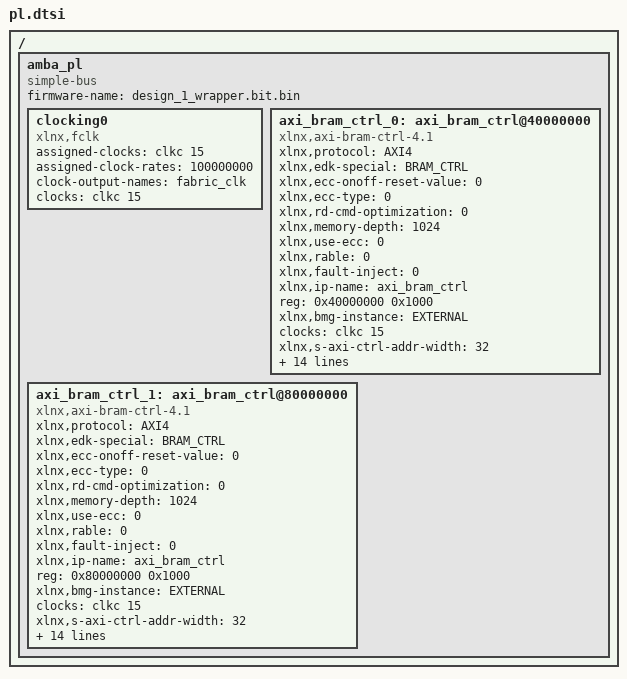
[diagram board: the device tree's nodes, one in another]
/ {
	amba_pl: amba_pl {
		ranges;
		compatible = "simple-bus";
		#address-cells = <1>;
		#size-cells = <1>;
		firmware-name = "design_1_wrapper.bit.bin";
		clocking0: clocking0 {
			compatible = "xlnx,fclk";
			assigned-clocks = <&clkc 15>;
			assigned-clock-rates = <100000000>;
			#clock-cells = <0>;
			clock-output-names = "fabric_clk";
			clocks = <&clkc 15>;
		};
		axi_bram_ctrl_0: axi_bram_ctrl@40000000 {
			xlnx,protocol = "AXI4";
			xlnx,edk-special = "BRAM_CTRL";
			compatible = "xlnx,axi-bram-ctrl-4.1";
			xlnx,ecc-onoff-reset-value = <0>;
			xlnx,ecc-type = <0>;
			xlnx,rd-cmd-optimization = <0>;
			xlnx,memory-depth = <1024>;
			xlnx,use-ecc = <0>;
			xlnx,rable = <0>;
			xlnx,fault-inject = <0>;
			xlnx,ip-name = "axi_bram_ctrl";
			reg = <0x40000000 0x1000>;
			xlnx,bmg-instance = "EXTERNAL";
			clocks = <&clkc 15>;
			xlnx,s-axi-ctrl-addr-width = <32>;
			xlnx,read-latency = <1>;
			xlnx,id-width = <0>;
			xlnx,s-axi-supports-narrow-burst = <0>;
			xlnx,supports-narrow-burst = <0>;
			xlnx,single-port-bram = <1>;
			xlnx,ecc = <0>;
			xlnx,edk-iptype = "PERIPHERAL";
			status = "okay";
			clock-names = "s_axi_aclk";
			xlnx,data-width = <32>;
			xlnx,bram-addr-width = <10>;
			xlnx,bram-inst-mode = "EXTERNAL";
			xlnx,s-axi-ctrl-data-width = <32>;
			xlnx,mem-depth = <1024>;
			xlnx,s-axi-id-width = <1>;
			xlnx,name = "axi_bram_ctrl_0";
		};
		axi_bram_ctrl_1: axi_bram_ctrl@80000000 {
			xlnx,protocol = "AXI4";
			xlnx,edk-special = "BRAM_CTRL";
			compatible = "xlnx,axi-bram-ctrl-4.1";
			xlnx,ecc-onoff-reset-value = <0>;
			xlnx,ecc-type = <0>;
			xlnx,rd-cmd-optimization = <0>;
			xlnx,memory-depth = <1024>;
			xlnx,use-ecc = <0>;
			xlnx,rable = <0>;
			xlnx,fault-inject = <0>;
			xlnx,ip-name = "axi_bram_ctrl";
			reg = <0x80000000 0x1000>;
			xlnx,bmg-instance = "EXTERNAL";
			clocks = <&clkc 15>;
			xlnx,s-axi-ctrl-addr-width = <32>;
			xlnx,read-latency = <1>;
			xlnx,id-width = <0>;
			xlnx,s-axi-supports-narrow-burst = <0>;
			xlnx,supports-narrow-burst = <0>;
			xlnx,single-port-bram = <1>;
			xlnx,ecc = <0>;
			xlnx,edk-iptype = "PERIPHERAL";
			status = "okay";
			clock-names = "s_axi_aclk";
			xlnx,data-width = <32>;
			xlnx,bram-addr-width = <10>;
			xlnx,bram-inst-mode = "EXTERNAL";
			xlnx,s-axi-ctrl-data-width = <32>;
			xlnx,mem-depth = <1024>;
			xlnx,s-axi-id-width = <1>;
			xlnx,name = "axi_bram_ctrl_1";
		};
	};
};
